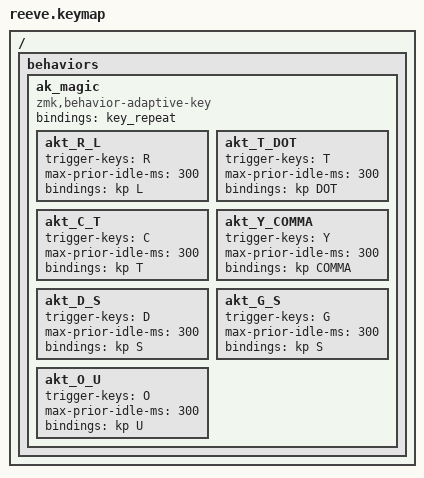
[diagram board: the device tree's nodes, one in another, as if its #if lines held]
#include <behaviors.dtsi>
#include <behaviors/num_word.dtsi> // Requires auto-layer module.
#include <dt-bindings/zmk/keys.h>
#ifdef CONFIG_WIRELESS
  #include <dt-bindings/zmk/bt.h>
  #include <dt-bindings/zmk/outputs.h>
  #define _BT_SEL_KEYS_                                                        \
      &bt BT_SEL 0 &bt BT_SEL 1 &bt BT_SEL 2 &bt BT_SEL 3 &bt BT_CLR
#else
  #define _BT_SEL_KEYS_ &trans &trans &trans &trans &trans
#endif

#include "zmk-helpers/helper.h"
// #include "zmk-helpers/unicode-chars/greek.dtsi"
// #include "zmk-helpers/unicode-chars/german.dtsi"

#define DEF 0
#define NAV 1
#define FN 2
#define NUM 3
#define SYS 4
#define MOUSE 5

#define XXX &none
#define ___ &trans

#ifndef ZMK_BASE_LAYER
  #define ZMK_BASE_LAYER(name, LT, RT, LM, RM, LB, RB, LH, RH)                 \
      ZMK_LAYER(name, LT RT LM RM LB RB LH RH)
#endif

#include "zmk-helpers/helper.h"
// chog (lenchog) (2 likes)
//   q b g . z  v w o y f
//   r n s t m  k * a i h
//   l p d c j  x u ; , '
//                e   

// "rules": {
//   "r": "l",
//   "t": ".",
//   "c": "t",
//   "y": ",",
//   "d": "s",
//   "g": "s",
//   "o": "u",
//   "default": {
//     "type": "repeat"
//   }

 / {
    behaviors {
        ak_magic: ak_magic {
            compatible = "zmk,behavior-adaptive-key";
            #binding-cells = <0>;
            bindings = <&key_repeat>;

            akt_R_L { trigger-keys = <R>; max-prior-idle-ms = <300>; bindings = <&kp L>; };
            akt_T_DOT { trigger-keys = <T>; max-prior-idle-ms = <300>; bindings = <&kp DOT>; };
            akt_C_T { trigger-keys = <C>; max-prior-idle-ms = <300>; bindings = <&kp T>; };
            akt_Y_COMMA { trigger-keys = <Y>; max-prior-idle-ms = <300>; bindings = <&kp COMMA>; };
            akt_D_S { trigger-keys = <D>; max-prior-idle-ms = <300>; bindings = <&kp S>; };
            akt_G_S { trigger-keys = <G>; max-prior-idle-ms = <300>; bindings = <&kp S>; };
            akt_O_U { trigger-keys = <O>; max-prior-idle-ms = <300>; bindings = <&kp U>; };

        };
    };
 };

#define COMBO_TERM_FAST 18
#define COMBO_TERM_SLOW 30

#define COMBO_IDLE_FAST 150
#define COMBO_IDLE_SLOW 50
#define XXX &none
#define ___ &trans
ZMK_COMBO(v,   &kp V,           LTR LTM,     DEF, COMBO_TERM_FAST, COMBO_IDLE_FAST)
ZMK_COMBO(q,   &kp Q,           LBM LBI,     DEF, COMBO_TERM_FAST, COMBO_IDLE_FAST)
ZMK_COMBO(z,   &kp Z,           LBR LBM,     DEF, COMBO_TERM_FAST, COMBO_IDLE_FAST)
ZMK_COMBO(qu,  &kp Q &kp U,     LTM LTI,     DEF, COMBO_TERM_FAST, COMBO_IDLE_FAST)


ZMK_BASE_LAYER(DEF,
//╭─────────────┬─────────────┬─────────────┬─────────────┬─────────────╮ ╭─────────────┬─────────────┬─────────────┬─────────────┬─────────────╮
    ___           &kp W         &kp F         &kp P       &kp B       ,   &kp X         &kp L         &kp U         &kp Y         &kp SQT       ,
//├─────────────┼─────────────┼─────────────┼─────────────┼─────────────┤ ├─────────────┼─────────────┼─────────────┼─────────────┼─────────────┤
    &kp R         &kp S         &kp T         &kp H         &kp K       ,   &kp J         &kp N         &kp A         &kp I         &kp O       ,
//├─────────────┼─────────────┼─────────────┼─────────────┼─────────────┤ ├─────────────┼─────────────┼─────────────┼─────────────┼─────────────┤
    ___           &kp C         &kp G         &kp D         ___         ,   ___           &kp M         &kp SEMI      &kp COMMA     &kp F     ,
//╰─────────────┼─────────────┴─────────────┼─────────────┼─────────────┤ ├─────────────┼─────────────┼─────────────┴───────────────────────────╯
                                              &kp BSPC      &kp E       ,   &kp SPACE     &kp TAB
//                                          ╰─────────────┴─────────────╯ ╰─────────────┴─────────────╯
)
